VERSION ""
NS_ :

BS_:
BU_: RVCController RVCNode

// DM_RV from SA=0x9D (0x80000000|0x18FECA9D = 2566834845)
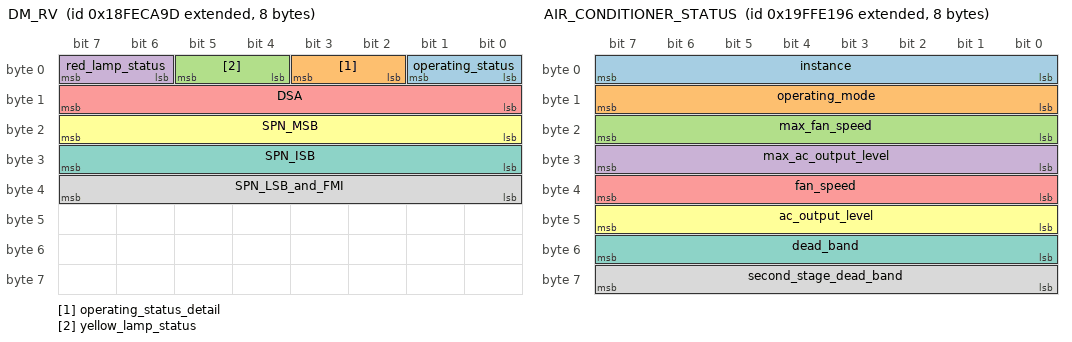
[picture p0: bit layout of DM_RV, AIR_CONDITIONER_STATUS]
BO_ 2566834845 DM_RV: 8 RVCNode
    SG_ operating_status           :  0|2@1+ (1,0)   [0|3]    "" RVCController
    SG_ operating_status_detail    :  2|2@1+ (1,0)   [0|3]    "" RVCController
    SG_ yellow_lamp_status         :  4|2@1+ (1,0)   [0|3]    "" RVCController
    SG_ red_lamp_status            :  6|2@1+ (1,0)   [0|3]    "" RVCController
    SG_ DSA                         :  8|8@1+ (1,0)   [0|255]  "" RVCController
    SG_ SPN_MSB                     : 16|8@1+ (1,0)   [0|255]  "" RVCController
    SG_ SPN_ISB                     : 24|8@1+ (1,0)   [0|255]  "" RVCController
    SG_ SPN_LSB_and_FMI             : 32|8@1+ (1,0)   [0|255]  "" RVCController

// AIR_CONDITIONER_STATUS from SA=0x96 (0x80000000|0x19FFE196 = 2583683478)
BO_ 2583683478 AIR_CONDITIONER_STATUS: 8 RVCNode
    SG_ instance                   :  0|8@1+ (1,0)   [0|255] "" RVCController
    SG_ operating_mode             :  8|8@1+ (1,0)   [0|255] "" RVCController
    SG_ max_fan_speed              : 16|8@1+ (0.5,0) [0|100] "%" RVCController
    SG_ max_ac_output_level        : 24|8@1+ (0.5,0) [0|100] "%" RVCController
    SG_ fan_speed                  : 32|8@1+ (0.5,0) [0|100] "%" RVCController
    SG_ ac_output_level            : 40|8@1+ (0.5,0) [0|100] "%" RVCController
    SG_ dead_band                  : 48|8@1+ (0.1,0) [0|25]  "°C" RVCController
    SG_ second_stage_dead_band     : 56|8@1+ (0.1,0) [0|25]  "°C" RVCController

// DM_RV from SA=0x9C (0x80000000|0x18FECA9C = 2566834844)
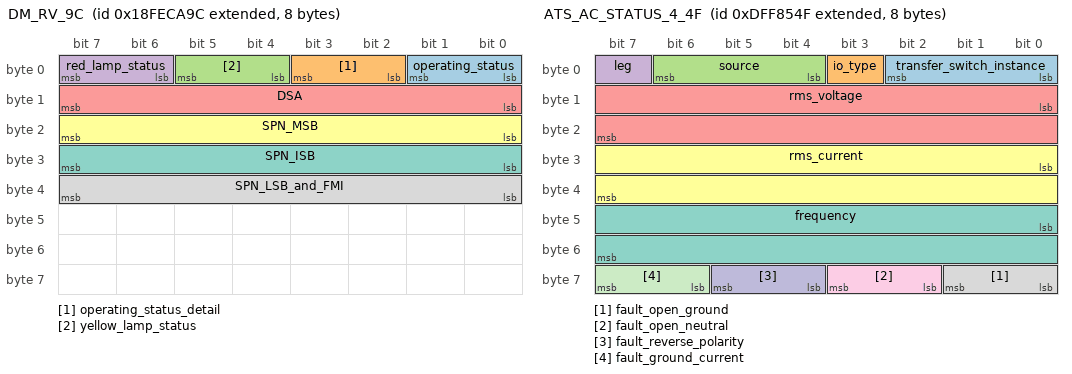
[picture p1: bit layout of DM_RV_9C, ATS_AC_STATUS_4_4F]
BO_ 2566834844 DM_RV_9C: 8 RVCNode
    SG_ operating_status           :  0|2@1+ (1,0)   [0|3]   "" RVCController
    SG_ operating_status_detail    :  2|2@1+ (1,0)   [0|3]   "" RVCController
    SG_ yellow_lamp_status         :  4|2@1+ (1,0)   [0|3]   "" RVCController
    SG_ red_lamp_status            :  6|2@1+ (1,0)   [0|3]   "" RVCController
    SG_ DSA                         :  8|8@1+ (1,0)   [0|255] "" RVCController
    SG_ SPN_MSB                     : 16|8@1+ (1,0)   [0|255] "" RVCController
    SG_ SPN_ISB                     : 24|8@1+ (1,0)   [0|255] "" RVCController
    SG_ SPN_LSB_and_FMI             : 32|8@1+ (1,0)   [0|255] "" RVCController

// ATS_AC_STATUS_4 from SA=0x4F (0x80000000|0x0DFF854F = 2382333263)
BO_ 2382333263 ATS_AC_STATUS_4_4F: 8 RVCNode
    SG_ transfer_switch_instance   :  0|3@1+ (1,0) [0|7]   "" RVCController
    SG_ io_type                     :  3|1@1+ (1,0) [0|1]   "" RVCController
    SG_ source                      :  4|3@1+ (1,0) [0|7]   "" RVCController
    SG_ leg                         :  7|1@1+ (1,0) [0|1]   "" RVCController
    SG_ rms_voltage                 :  8|16@1+ (0.1,0) [0|6553.5] "Vac" RVCController
    SG_ rms_current                 : 24|16@1+ (0.1,0) [0|6553.5] "Aac" RVCController
    SG_ frequency                   : 40|16@1+ (0.0078125,0) [0|500] "Hz" RVCController
    SG_ fault_open_ground           : 56|2@1+ (1,0) [0|3]   "" RVCController
    SG_ fault_open_neutral          : 58|2@1+ (1,0) [0|3]   "" RVCController
    SG_ fault_reverse_polarity      : 60|2@1+ (1,0) [0|3]   "" RVCController
    SG_ fault_ground_current        : 62|2@1+ (1,0) [0|3]   "" RVCController

// AIR_CONDITIONER_COMMAND (DGN = 0x1FFE0) from SA=0x9D
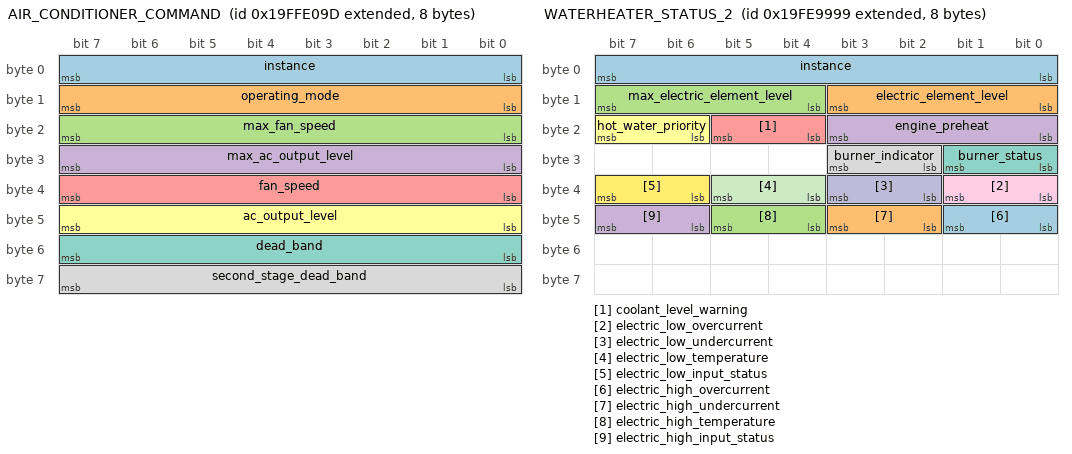
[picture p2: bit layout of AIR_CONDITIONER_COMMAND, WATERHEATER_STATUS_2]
BO_ 2583683229 AIR_CONDITIONER_COMMAND: 8 RVCNode
    SG_ instance                   :   0| 8@1+ (1,0)    [0|255]   ""    RVCController
    SG_ operating_mode             :   8| 8@1+ (1,0)    [0|255]   ""    RVCController
    SG_ max_fan_speed              :  16| 8@1+ (0.4,0)  [0|100]  "Pct"  RVCController
    SG_ max_ac_output_level        :  24| 8@1+ (0.4,0)  [0|100]  "Pct"  RVCController
    SG_ fan_speed                  :  32| 8@1+ (0.4,0)  [0|100]  "Pct"  RVCController
    SG_ ac_output_level            :  40| 8@1+ (0.4,0)  [0|100]  "Pct"  RVCController
    SG_ dead_band                  :  48| 8@1+ (1,0)    [0|255]   ""    RVCController
    SG_ second_stage_dead_band     :  56| 8@1+ (1,0)    [0|255]   ""    RVCController

// WATERHEATER_STATUS_2 (DGN = 0x1FE99) from SA=0x99
BO_ 2583599513 WATERHEATER_STATUS_2: 8 RVCNode
    SG_ instance                      :   0| 8@1+ (1,0)    [0|255]   ""    RVCController
    SG_ electric_element_level        :   8| 4@1+ (1,0)    [0|15]    ""    RVCController
    SG_ max_electric_element_level    :  12| 4@1+ (1,0)    [0|15]    ""    RVCController
    SG_ engine_preheat                :  16| 4@1+ (1,0)    [0|15]    ""    RVCController
    SG_ coolant_level_warning         :  20| 2@1+ (1,0)    [0|3]     ""    RVCController
    SG_ hot_water_priority            :  22| 2@1+ (1,0)    [0|3]     ""    RVCController
    SG_ burner_status                 :  24| 2@1+ (1,0)    [0|3]     ""    RVCController
    SG_ burner_indicator              :  26| 2@1+ (1,0)    [0|3]     ""    RVCController
    SG_ electric_low_overcurrent      :  32| 2@1+ (1,0)    [0|3]     ""    RVCController
    SG_ electric_low_undercurrent     :  34| 2@1+ (1,0)    [0|3]     ""    RVCController
    SG_ electric_low_temperature      :  36| 2@1+ (1,0)    [0|3]     ""    RVCController
    SG_ electric_low_input_status     :  38| 2@1+ (1,0)    [0|3]     ""    RVCController
    SG_ electric_high_overcurrent     :  40| 2@1+ (1,0)    [0|3]     ""    RVCController
    SG_ electric_high_undercurrent    :  42| 2@1+ (1,0)    [0|3]     ""    RVCController
    SG_ electric_high_temperature     :  44| 2@1+ (1,0)    [0|3]     ""    RVCController
    SG_ electric_high_input_status    :  46| 2@1+ (1,0)    [0|3]     ""    RVCController

// CIRCULATION_PUMP_STATUS (DGN = 0x1FE97) from SA=0x99
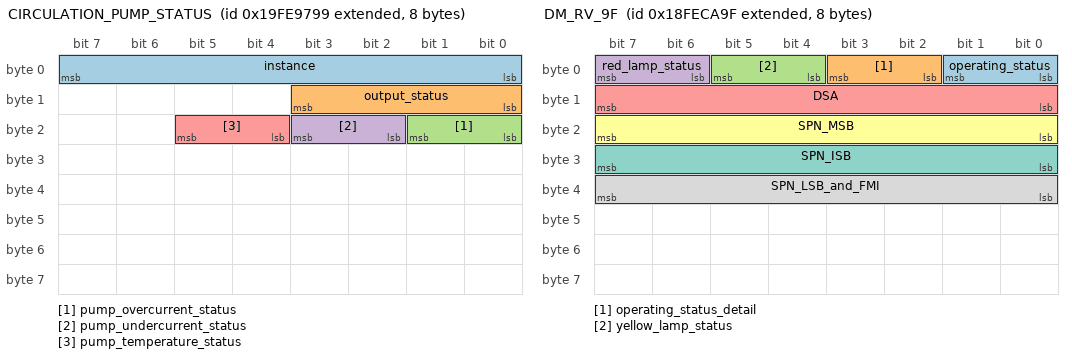
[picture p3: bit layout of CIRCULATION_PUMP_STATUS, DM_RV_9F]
BO_ 2583599001 CIRCULATION_PUMP_STATUS: 8 RVCNode
    SG_ instance                   :   0| 8@1+ (1,0)    [0|255]   ""    RVCController
    SG_ output_status              :   8| 4@1+ (1,0)    [0|15]    ""    RVCController
    SG_ pump_overcurrent_status    :  16| 2@1+ (1,0)    [0|3]     ""    RVCController
    SG_ pump_undercurrent_status   :  18| 2@1+ (1,0)    [0|3]     ""    RVCController
    SG_ pump_temperature_status    :  20| 2@1+ (1,0)    [0|3]     ""    RVCController

// DM_RV from SA=0x9F (DGN = 1FECAh, extended ID = 0x98FECA9F = 2566834847)
BO_ 2566834847 DM_RV_9F: 8 RVCNode
    SG_ operating_status        :   0|2@1+ (1,0)   [0|3]     "" RVCController
    SG_ operating_status_detail :   2|2@1+ (1,0)   [0|3]     "" RVCController
    SG_ yellow_lamp_status      :   4|2@1+ (1,0)   [0|3]     "" RVCController
    SG_ red_lamp_status         :   6|2@1+ (1,0)   [0|3]     "" RVCController
    SG_ DSA                     :   8|8@1+ (1,0)   [0|255]   "" RVCController
    SG_ SPN_MSB                 :  16|8@1+ (1,0)   [0|255]   "" RVCController
    SG_ SPN_ISB                 :  24|8@1+ (1,0)   [0|255]   "" RVCController
    SG_ SPN_LSB_and_FMI         :  32|8@1+ (1,0)   [0|255]   "" RVCController

// DC_MOTOR_CONTROL_STATUS (DGN = 0x1FEE0) from SA = 0x9D
// Defined in § 6.27.2 of the RV-C spec :contentReference[oaicite:0]{index=0}
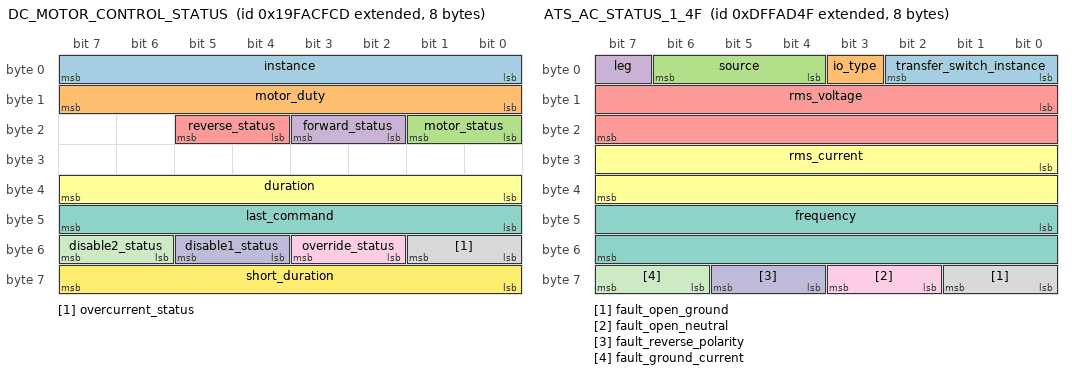
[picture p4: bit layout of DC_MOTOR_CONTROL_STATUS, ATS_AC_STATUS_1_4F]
BO_ 2583351245 DC_MOTOR_CONTROL_STATUS: 8 RVCNode
    SG_ instance            :  0| 8@1+ (1,0)   [0|250]  ""   RVCController
    SG_ motor_duty          :  8| 8@1+ (0.4,0) [0|100] "%"  RVCController
    SG_ motor_status        : 16| 2@1+ (1,0)   [0|3]    ""   RVCController
    SG_ forward_status      : 18| 2@1+ (1,0)   [0|3]    ""   RVCController
    SG_ reverse_status      : 20| 2@1+ (1,0)   [0|3]    ""   RVCController
    SG_ duration            : 32| 8@1+ (1,0)   [0|240] "s"  RVCController
    SG_ last_command        : 40| 8@1+ (1,0)   [0|255] ""   RVCController
    SG_ overcurrent_status  : 48| 2@1+ (1,0)   [0|3]    ""   RVCController
    SG_ override_status     : 50| 2@1+ (1,0)   [0|3]    ""   RVCController
    SG_ disable1_status     : 52| 2@1+ (1,0)   [0|3]    ""   RVCController
    SG_ disable2_status     : 54| 2@1+ (1,0)   [0|3]    ""   RVCController
    SG_ short_duration      : 56| 8@1+ (5,0)   [0|1275] "ms" RVCController

// ATS_AC_STATUS_1 from SA=0x4F (DGN=0x1FFAD, ext ID = 0x8DFFAD4F = 2382343503)
BO_ 2382343503 ATS_AC_STATUS_1_4F: 8 RVCNode
    SG_ transfer_switch_instance :   0| 3@1+ (1,0)   [0|7]    "" RVCController
    SG_ io_type                  :   3| 1@1+ (1,0)   [0|1]    "" RVCController
    SG_ source                   :   4| 3@1+ (1,0)   [0|7]    "" RVCController
    SG_ leg                      :   7| 1@1+ (1,0)   [0|1]    "" RVCController
    SG_ rms_voltage              :   8|16@1+ (0.1,0) [0|6553.5] "Vac" RVCController
    SG_ rms_current              :  24|16@1+ (0.1,0) [0|6553.5] "Aac" RVCController
    SG_ frequency                :  40|16@1+ (0.0078125,0) [0|500] "Hz" RVCController
    SG_ fault_open_ground        :  56| 2@1+ (1,0)   [0|3]    "" RVCController
    SG_ fault_open_neutral       :  58| 2@1+ (1,0)   [0|3]    "" RVCController
    SG_ fault_reverse_polarity   :  60| 2@1+ (1,0)   [0|3]    "" RVCController
    SG_ fault_ground_current     :  62| 2@1+ (1,0)   [0|3]    "" RVCController

// DM_RV from SA=0x95 (DGN=0x1FECA, ext ID = 0x98FECA95 = 2566834837)
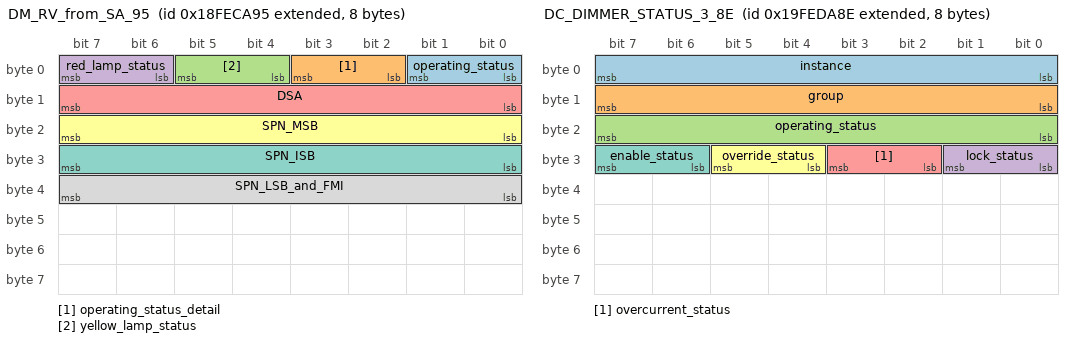
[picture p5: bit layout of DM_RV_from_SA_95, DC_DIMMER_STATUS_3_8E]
BO_ 2566834837 DM_RV_from_SA_95: 8 RVCNode
    SG_ operating_status        :   0| 2@1+ (1,0) [0|3]    "" RVCController
    SG_ operating_status_detail :   2| 2@1+ (1,0) [0|3]    "" RVCController
    SG_ yellow_lamp_status      :   4| 2@1+ (1,0) [0|3]    "" RVCController
    SG_ red_lamp_status         :   6| 2@1+ (1,0) [0|3]    "" RVCController
    SG_ DSA                     :   8| 8@1+ (1,0) [0|255]  "" RVCController
    SG_ SPN_MSB                 :  16| 8@1+ (1,0) [0|255]  "" RVCController
    SG_ SPN_ISB                 :  24| 8@1+ (1,0) [0|255]  "" RVCController
    SG_ SPN_LSB_and_FMI         :  32| 8@1+ (1,0) [0|255]  "" RVCController

// DC_DIMMER_STATUS_3 from SA=0x8E (DGN=0x1FEDA, ext ID = 0x99FEDA8E = 2583616142)
BO_ 2583616142 DC_DIMMER_STATUS_3_8E: 8 RVCNode
    SG_ instance            :   0| 8@1+ (1,0)   [0|250]  ""   RVCController
    SG_ group               :   8| 8@1+ (1,0)   [0|255]  ""   RVCController
    SG_ operating_status    :  16| 8@1+ (1,0)   [0|255]  ""   RVCController
    SG_ lock_status         :  24| 2@1+ (1,0)   [0|3]    ""   RVCController
    SG_ overcurrent_status  :  26| 2@1+ (1,0)   [0|3]    ""   RVCController
    SG_ override_status     :  28| 2@1+ (1,0)   [0|3]    ""   RVCController
    SG_ enable_status       :  30| 2@1+ (1,0)   [0|3]    ""   RVCController

// WEATHER_WIND_STATUS from SA=0x8E (0x80000000 | 0x19FEDA8E = 2583059206)
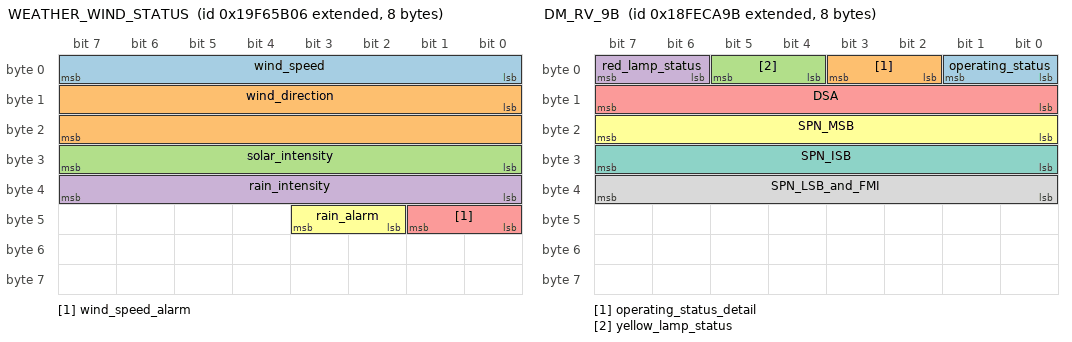
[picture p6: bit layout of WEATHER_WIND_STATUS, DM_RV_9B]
BO_ 2583059206 WEATHER_WIND_STATUS: 8 RVCNode
    SG_ wind_speed                 :   0| 8@1+ (1,0)     [0|250]   "kph"   RVCController
    SG_ wind_direction             :   8|16@1+ (0.0078125,0) [0|359]   "deg"   RVCController
    SG_ solar_intensity            :  24| 8@1+ (1,0)     [0|250]   "kLux"  RVCController
    SG_ rain_intensity             :  32| 8@1+ (1,0)     [0|100]   "%"     RVCController
    SG_ wind_speed_alarm           :  40| 2@1+ (1,0)     [0|3]     ""      RVCController
    SG_ rain_alarm                 :  42| 2@1+ (1,0)     [0|3]     ""      RVCController

// DM_RV from SA=0x9B (0x18FECA9B = 419351195)
BO_ 2566834843 DM_RV_9B: 8 RVCNode
    SG_ operating_status        :   0|2@1+ (1,0)   [0|3]    "" RVCController
    SG_ operating_status_detail :   2|2@1+ (1,0)   [0|3]    "" RVCController
    SG_ yellow_lamp_status      :   4|2@1+ (1,0)   [0|3]    "" RVCController
    SG_ red_lamp_status         :   6|2@1+ (1,0)   [0|3]    "" RVCController
    SG_ DSA                     :   8|8@1+ (1,0)   [0|255]  "" RVCController
    SG_ SPN_MSB                 :  16|8@1+ (1,0)   [0|255]  "" RVCController
    SG_ SPN_ISB                 :  24|8@1+ (1,0)   [0|255]  "" RVCController
    SG_ SPN_LSB_and_FMI         :  32|8@1+ (1,0)   [0|255]  "" RVCController

// DM_RV from SA=0x97 (0x18FECA97 = 419351191)
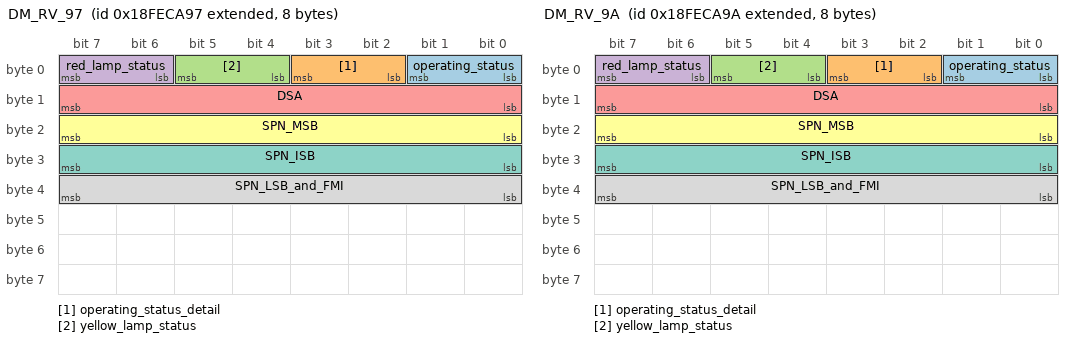
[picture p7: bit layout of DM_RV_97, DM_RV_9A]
BO_ 2566834839 DM_RV_97: 8 RVCNode
    SG_ operating_status        :   0|2@1+ (1,0)   [0|3]    "" RVCController
    SG_ operating_status_detail :   2|2@1+ (1,0)   [0|3]    "" RVCController
    SG_ yellow_lamp_status      :   4|2@1+ (1,0)   [0|3]    "" RVCController
    SG_ red_lamp_status         :   6|2@1+ (1,0)   [0|3]    "" RVCController
    SG_ DSA                     :   8|8@1+ (1,0)   [0|255]  "" RVCController
    SG_ SPN_MSB                 :  16|8@1+ (1,0)   [0|255]  "" RVCController
    SG_ SPN_ISB                 :  24|8@1+ (1,0)   [0|255]  "" RVCController
    SG_ SPN_LSB_and_FMI         :  32|8@1+ (1,0)   [0|255]  "" RVCController

// DM_RV from SA=0x9A (0x18FECA9A = 419351194)
BO_ 2566834842 DM_RV_9A: 8 RVCNode
    SG_ operating_status        :   0|2@1+ (1,0)   [0|3]    "" RVCController
    SG_ operating_status_detail :   2|2@1+ (1,0)   [0|3]    "" RVCController
    SG_ yellow_lamp_status      :   4|2@1+ (1,0)   [0|3]    "" RVCController
    SG_ red_lamp_status         :   6|2@1+ (1,0)   [0|3]    "" RVCController
    SG_ DSA                     :   8|8@1+ (1,0)   [0|255]  "" RVCController
    SG_ SPN_MSB                 :  16|8@1+ (1,0)   [0|255]  "" RVCController
    SG_ SPN_ISB                 :  24|8@1+ (1,0)   [0|255]  "" RVCController
    SG_ SPN_LSB_and_FMI         :  32|8@1+ (1,0)   [0|255]  "" RVCController

// DM_RV from SA=0x98 (0x18FECA98 = 419351192)
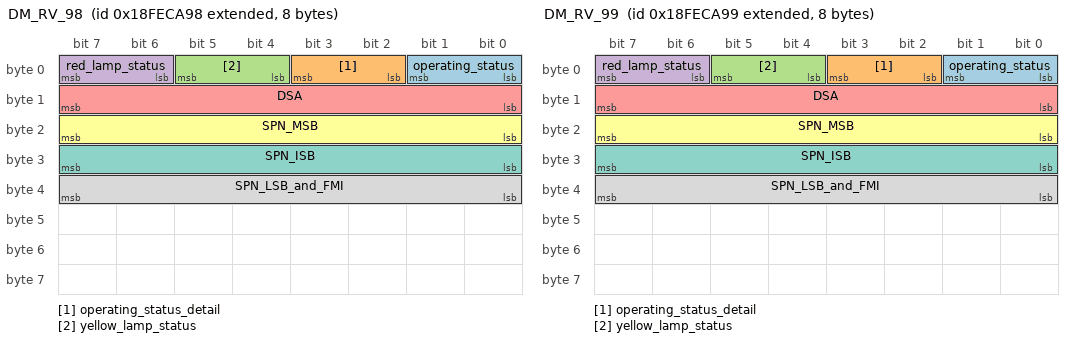
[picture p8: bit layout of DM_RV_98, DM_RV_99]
BO_ 2566834840 DM_RV_98: 8 RVCNode
    SG_ operating_status        :   0|2@1+ (1,0)   [0|3]    "" RVCController
    SG_ operating_status_detail :   2|2@1+ (1,0)   [0|3]    "" RVCController
    SG_ yellow_lamp_status      :   4|2@1+ (1,0)   [0|3]    "" RVCController
    SG_ red_lamp_status         :   6|2@1+ (1,0)   [0|3]    "" RVCController
    SG_ DSA                     :   8|8@1+ (1,0)   [0|255]  "" RVCController
    SG_ SPN_MSB                 :  16|8@1+ (1,0)   [0|255]  "" RVCController
    SG_ SPN_ISB                 :  24|8@1+ (1,0)   [0|255]  "" RVCController
    SG_ SPN_LSB_and_FMI         :  32|8@1+ (1,0)   [0|255]  "" RVCController

// DM_RV from SA=0x99 (0x18FECA99 = 419351193)
BO_ 2566834841 DM_RV_99: 8 RVCNode
    SG_ operating_status        :   0|2@1+ (1,0)   [0|3]    "" RVCController
    SG_ operating_status_detail :   2|2@1+ (1,0)   [0|3]    "" RVCController
    SG_ yellow_lamp_status      :   4|2@1+ (1,0)   [0|3]    "" RVCController
    SG_ red_lamp_status         :   6|2@1+ (1,0)   [0|3]    "" RVCController
    SG_ DSA                     :   8|8@1+ (1,0)   [0|255]  "" RVCController
    SG_ SPN_MSB                 :  16|8@1+ (1,0)   [0|255]  "" RVCController
    SG_ SPN_ISB                 :  24|8@1+ (1,0)   [0|255]  "" RVCController
    SG_ SPN_LSB_and_FMI         :  32|8@1+ (1,0)   [0|255]  "" RVCController

// AIR_CONDITIONER_STATUS from SA=0x97 (0x19FFE197 = 436199831)
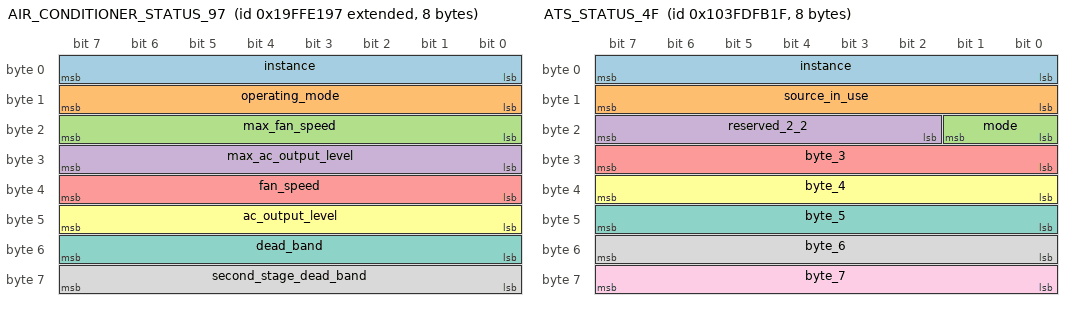
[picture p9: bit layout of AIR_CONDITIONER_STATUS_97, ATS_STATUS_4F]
BO_ 2583683479 AIR_CONDITIONER_STATUS_97: 8 RVCNode
    SG_ instance                  :   0|8@1+  (1,0)   [0|255] ""  RVCController
    SG_ operating_mode            :   8|8@1+  (1,0)   [0|255] ""  RVCController
    SG_ max_fan_speed             :  16|8@1+  (0.5,0) [0|100] "%" RVCController
    SG_ max_ac_output_level       :  24|8@1+  (0.5,0) [0|100] "%" RVCController
    SG_ fan_speed                 :  32|8@1+  (0.5,0) [0|100] "%" RVCController
    SG_ ac_output_level           :  40|8@1+  (0.5,0) [0|100] "%" RVCController
    SG_ dead_band                 :  48|8@1+  (0.1,0) [0|25]  "°C" RVCController
    SG_ second_stage_dead_band    :  56|8@1+  (0.1,0) [0|25]  "°C" RVCController

// ATS_STATUS from SA=0x4F (0x19FFAA4F = 4361943839)
BO_ 4361943839 ATS_STATUS_4F: 8 RVCNode
  VFrameFormat extended
    SG_ instance       :  0|8@1+ (1,0)   [1|6]   ""   RVCController
    SG_ source_in_use  :  8|8@1+ (1,0)   [0|253] ""   RVCController
    SG_ mode           : 16|2@1+ (1,0)   [0|3]   ""   RVCController
    SG_ reserved_2_2   : 18|6@1+ (1,0)   [0|63]  ""   RVCController
    SG_ byte_3         : 24|8@1+ (1,0)   [0|255] ""   RVCController
    SG_ byte_4         : 32|8@1+ (1,0)   [0|255] ""   RVCController
    SG_ byte_5         : 40|8@1+ (1,0)   [0|255] ""   RVCController
    SG_ byte_6         : 48|8@1+ (1,0)   [0|255] ""   RVCController
    SG_ byte_7         : 56|8@1+ (1,0)   [0|255] ""   RVCController

// UNKNOWN ENTRIES

// UNKNOWN_1FF2E (DGN = 1FF2Eh, extended ID = 0x98FF2E75 = 2566860405)
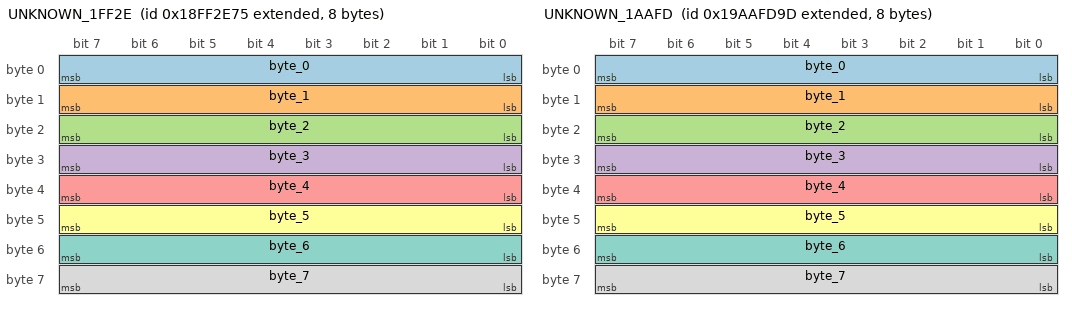
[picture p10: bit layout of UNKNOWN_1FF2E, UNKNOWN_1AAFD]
BO_ 2566860405 UNKNOWN_1FF2E: 8 RVCNode
    SG_ byte_0 :   0|8@1+ (1,0) [0|255] "" RVCController
    SG_ byte_1 :   8|8@1+ (1,0) [0|255] "" RVCController
    SG_ byte_2 :  16|8@1+ (1,0) [0|255] "" RVCController
    SG_ byte_3 :  24|8@1+ (1,0) [0|255] "" RVCController
    SG_ byte_4 :  32|8@1+ (1,0) [0|255] "" RVCController
    SG_ byte_5 :  40|8@1+ (1,0) [0|255] "" RVCController
    SG_ byte_6 :  48|8@1+ (1,0) [0|255] "" RVCController
    SG_ byte_7 :  56|8@1+ (1,0) [0|255] "" RVCController

// UNKNOWN_1AAFD (DGN = 1AAFDh, extended ID = 0x99AAFD9D = 2578120093)
BO_ 2578120093 UNKNOWN_1AAFD: 8 RVCNode
    SG_ byte_0 :   0|8@1+ (1,0) [0|255] "" RVCController
    SG_ byte_1 :   8|8@1+ (1,0) [0|255] "" RVCController
    SG_ byte_2 :  16|8@1+ (1,0) [0|255] "" RVCController
    SG_ byte_3 :  24|8@1+ (1,0) [0|255] "" RVCController
    SG_ byte_4 :  32|8@1+ (1,0) [0|255] "" RVCController
    SG_ byte_5 :  40|8@1+ (1,0) [0|255] "" RVCController
    SG_ byte_6 :  48|8@1+ (1,0) [0|255] "" RVCController
    SG_ byte_7 :  56|8@1+ (1,0) [0|255] "" RVCController

// UNKNOWN_1FACE (DGN = 0x1FACE) from SA=0x9D
// (0x80000000 | 0x19FACE9D = 2583350941)
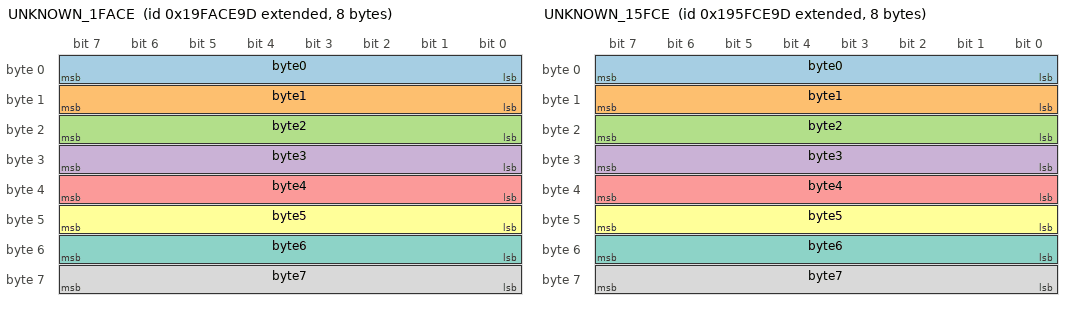
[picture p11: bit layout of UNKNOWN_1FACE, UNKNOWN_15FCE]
BO_ 2583350941 UNKNOWN_1FACE: 8 RVCNode
    SG_ byte0  :  0| 8@1+ (1,0) [0|255] "" RVCController
    SG_ byte1  :  8| 8@1+ (1,0) [0|255] "" RVCController
    SG_ byte2  : 16| 8@1+ (1,0) [0|255] "" RVCController
    SG_ byte3  : 24| 8@1+ (1,0) [0|255] "" RVCController
    SG_ byte4  : 32| 8@1+ (1,0) [0|255] "" RVCController
    SG_ byte5  : 40| 8@1+ (1,0) [0|255] "" RVCController
    SG_ byte6  : 48| 8@1+ (1,0) [0|255] "" RVCController
    SG_ byte7  : 56| 8@1+ (1,0) [0|255] "" RVCController

// UNKNOWN_15FCE (DGN = 0x15FCE) from SA=0x9D
// (0x80000000 | 0x195FCE9D = 2573192861)
BO_ 2573192861 UNKNOWN_15FCE: 8 RVCNode
    SG_ byte0  :  0| 8@1+ (1,0) [0|255] "" RVCController
    SG_ byte1  :  8| 8@1+ (1,0) [0|255] "" RVCController
    SG_ byte2  : 16| 8@1+ (1,0) [0|255] "" RVCController
    SG_ byte3  : 24| 8@1+ (1,0) [0|255] "" RVCController
    SG_ byte4  : 32| 8@1+ (1,0) [0|255] "" RVCController
    SG_ byte5  : 40| 8@1+ (1,0) [0|255] "" RVCController
    SG_ byte6  : 48| 8@1+ (1,0) [0|255] "" RVCController
    SG_ byte7  : 56| 8@1+ (1,0) [0|255] "" RVCController

// UNKNOWN_1FACF (DGN = 0x1FACF) from SA=0x9D
// Extended ID = 0x80000000 | 0x19FACF9D = 2583351197
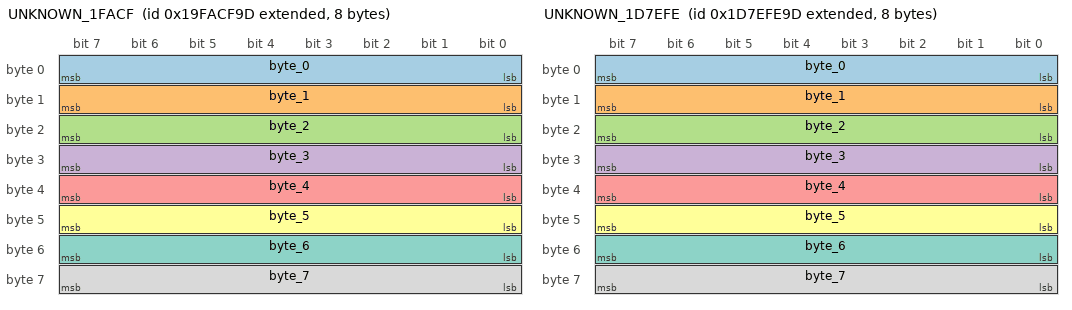
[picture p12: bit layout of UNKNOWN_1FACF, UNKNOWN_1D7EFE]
BO_ 2583351197 UNKNOWN_1FACF: 8 RVCNode
    SG_ byte_0 :  0| 8@1+ (1,0) [0|255] "" RVCController
    SG_ byte_1 :  8| 8@1+ (1,0) [0|255] "" RVCController
    SG_ byte_2 : 16| 8@1+ (1,0) [0|255] "" RVCController
    SG_ byte_3 : 24| 8@1+ (1,0) [0|255] "" RVCController
    SG_ byte_4 : 32| 8@1+ (1,0) [0|255] "" RVCController
    SG_ byte_5 : 40| 8@1+ (1,0) [0|255] "" RVCController
    SG_ byte_6 : 48| 8@1+ (1,0) [0|255] "" RVCController
    SG_ byte_7 : 56| 8@1+ (1,0) [0|255] "" RVCController

// UNKNOWN_1D7EFE (DGN = 0x1D7EFE) from SA=0x9D
// Extended ID = 0x80000000 | 0x1D7EFE9D = 2642345629
BO_ 2642345629 UNKNOWN_1D7EFE: 8 RVCNode
    SG_ byte_0 :  0| 8@1+ (1,0) [0|255] "" RVCController
    SG_ byte_1 :  8| 8@1+ (1,0) [0|255] "" RVCController
    SG_ byte_2 : 16| 8@1+ (1,0) [0|255] "" RVCController
    SG_ byte_3 : 24| 8@1+ (1,0) [0|255] "" RVCController
    SG_ byte_4 : 32| 8@1+ (1,0) [0|255] "" RVCController
    SG_ byte_5 : 40| 8@1+ (1,0) [0|255] "" RVCController
    SG_ byte_6 : 48| 8@1+ (1,0) [0|255] "" RVCController
    SG_ byte_7 : 56| 8@1+ (1,0) [0|255] "" RVCController

// UNKNOWN_19FED9 (DGN = 0x19FED9) from SA=0x9D
// Extended ID = 0x80000000 | 0x19FED99D = 2583615901
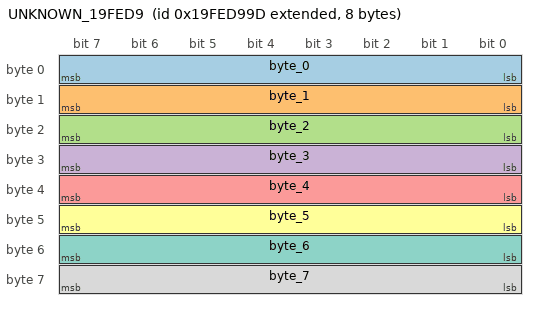
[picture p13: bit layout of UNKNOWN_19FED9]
BO_ 2583615901 UNKNOWN_19FED9: 8 RVCNode
    SG_ byte_0 :  0| 8@1+ (1,0) [0|255] "" RVCController
    SG_ byte_1 :  8| 8@1+ (1,0) [0|255] "" RVCController
    SG_ byte_2 : 16| 8@1+ (1,0) [0|255] "" RVCController
    SG_ byte_3 : 24| 8@1+ (1,0) [0|255] "" RVCController
    SG_ byte_4 : 32| 8@1+ (1,0) [0|255] "" RVCController
    SG_ byte_5 : 40| 8@1+ (1,0) [0|255] "" RVCController
    SG_ byte_6 : 48| 8@1+ (1,0) [0|255] "" RVCController
    SG_ byte_7 : 56| 8@1+ (1,0) [0|255] "" RVCController
